# ES32F36xx register map
File version: 1.0
Registers are 32-bit, read-write, reset 0x0 unless marked. A register's access mark holds for its fields unless they carry their own. Offsets are from the block's base; [hi:lo] are bit positions; {n}, {i} and the like mark numbered series; 'fields as' and 'values as' point back to an identical list.

## DBGC
Base 0x4004A000
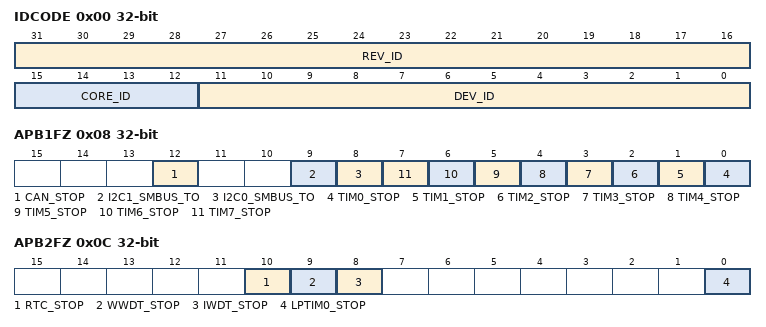
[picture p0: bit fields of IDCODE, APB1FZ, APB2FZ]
0x00 IDCODE read
  [31:16] REV_ID, [15:12] CORE_ID, [11:0] DEV_ID
0x08 APB1FZ
  [12] CAN_STOP, [9] I2C1_SMBUS_TO, [8] I2C0_SMBUS_TO, [n] TIM{n}_STOP (n=0..7)
0x0C APB2FZ
  [10] RTC_STOP, [9] WWDT_STOP, [8] IWDT_STOP, [0] LPTIM0_STOP

## QSPI
Base 0x4000D400
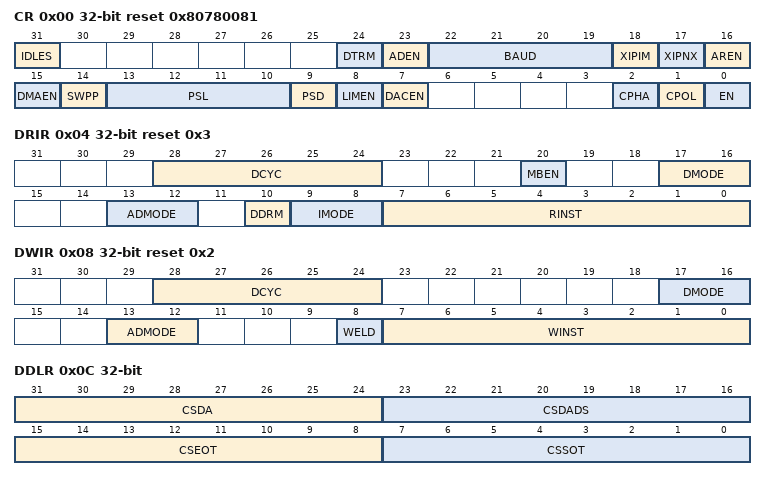
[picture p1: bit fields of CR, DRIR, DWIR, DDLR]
0x00 CR reset 0x80780081
  [31] IDLES read, [24] DTRM, [23] ADEN, [22:19] BAUD, [18] XIPIM, [17] XIPNX, [16] AREN, [15] DMAEN, [14] SWPP, [13:10] PSL, [9] PSD, [8] LIMEN, [7] DACEN, [2] CPHA, [1] CPOL, [0] EN
0x04 DRIR reset 0x3
  [28:24] DCYC, [20] MBEN, [17:16] DMODE, [13:12] ADMODE, [10] DDRM, [9:8] IMODE, [7:0] RINST
0x08 DWIR reset 0x2
  [28:24] DCYC, [17:16] DMODE, [13:12] ADMODE, [8] WELD, [7:0] WINST
0x0C DDLR
  [31:24] CSDA, [23:16] CSDADS, [15:8] CSEOT, [7:0] CSSOT
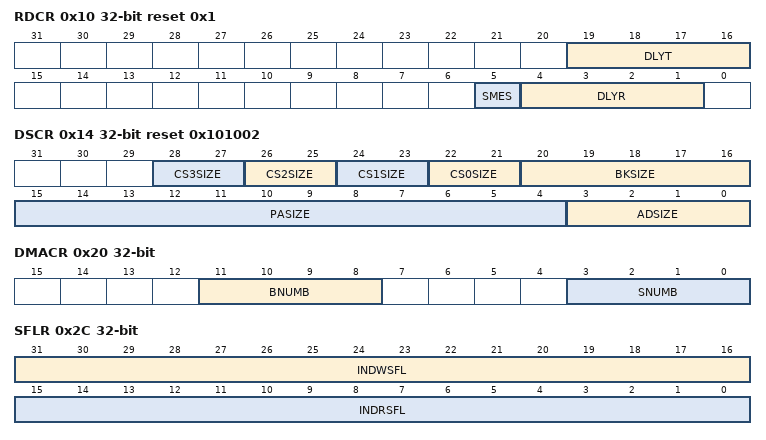
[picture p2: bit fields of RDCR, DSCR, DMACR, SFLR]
0x10 RDCR reset 0x1
  [19:16] DLYT, [5] SMES, [4:1] DLYR
0x14 DSCR reset 0x101002
  [2n+22:2n+21] CS{n}SIZE (n=0..3), [20:16] BKSIZE, [15:4] PASIZE, [3:0] ADSIZE
0x18 SPR reset 0x20
  [7:0] SRAMPS
0x1C IATR
  [31:0] INDTAD
0x20 DMACR
  [11:8] BNUMB, [3:0] SNUMB
0x24 RAR
  [31:0] READDR
0x28 MBR
  [7:0] MODEB
0x2C SFLR read
  [31:16] INDWSFL, [15:0] INDRSFL
0x30 TXHR reset 0x1
  [4:0] TXTH
0x34 RXHR reset 0x1
  [4:0] RXTH
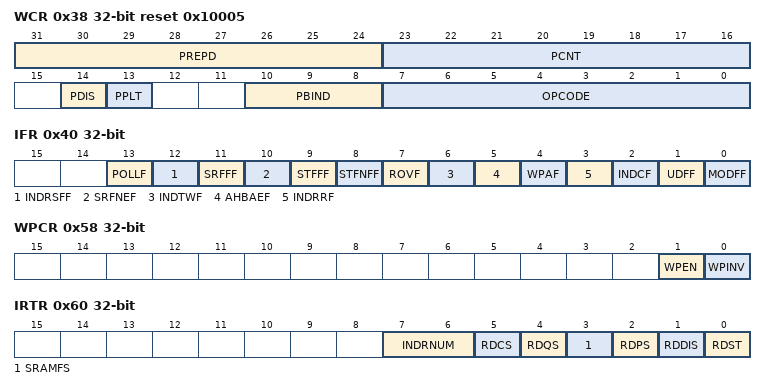
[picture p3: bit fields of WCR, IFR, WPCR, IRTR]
0x38 WCR reset 0x10005
  [31:24] PREPD, [23:16] PCNT, [14] PDIS, [13] PPLT, [10:8] PBIND, [7:0] OPCODE
0x3C PER reset 0xFFFFFFFF
  [31:0] PCYCN
0x40 IFR write1
  [13] POLLF read-clear-write1, [12] INDRSFF read-clear-write1, [11] SRFFF read-clear-write1, [10] SRFNEF read-clear-write1, [9] STFFF read-clear-write1, [8] STFNFF read-clear-write1, [7] ROVF read-clear-write1, [6] INDTWF read-clear-write1, [5] AHBAEF read-clear-write1, [4] WPAF read-clear-write1, [3] INDRRF read-clear-write1, [2] INDCF read-clear-write1, [1] UDFF read-clear-write1, [0] MODFF read-clear-write1
0x44 IMR
  [13:0] INTEN
0x50 WPLR
  [31:0] LBLKNUM
0x54 WPHR
  [31:0] HBLKNUM
0x58 WPCR
  [1] WPEN, [0] WPINV
0x60 IRTR write1
  [7:6] INDRNUM read, [5] RDCS read-clear-write1, [4] RDQS read, [3] SRAMFS read-clear-write1, [2] RDPS read, [1] RDDIS, [0] RDST
0x64 IRTWR
  [31:0] VAULE
0x68 IRTSAR
  [31:0] ADDR
0x6C IRTNR
  [31:0] NUM
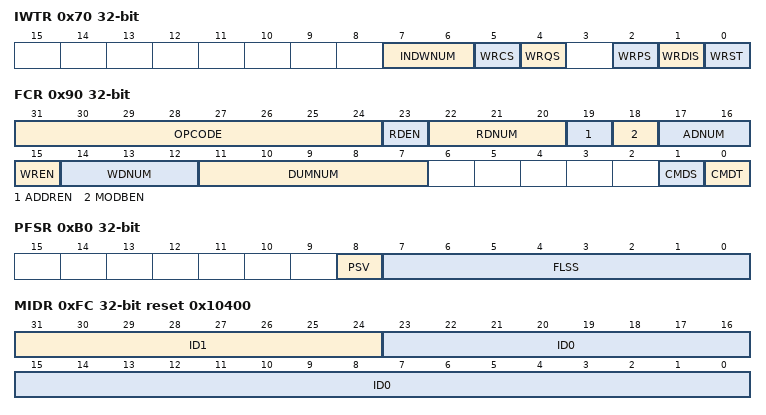
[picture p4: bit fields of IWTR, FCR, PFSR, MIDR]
0x70 IWTR write1
  [7:6] INDWNUM read, [5] WRCS read-clear-write1, [4] WRQS read, [2] WRPS read, [1] WRDIS, [0] WRST
0x74 IWTWR reset 0xFFFFFFFF
  [31:0] VAULE
0x78 IWTSAR
  [31:0] ADDR
0x7C IWTNR
  [31:0] NUM
0x80 ITARR reset 0x4
  [3:0] RNGW
0x90 FCR write1
  [31:24] OPCODE rw, [23] RDEN rw, [22:20] RDNUM rw, [19] ADDREN rw, [18] MODBEN rw, [17:16] ADNUM rw, [15] WREN rw, [14:12] WDNUM rw, [11:7] DUMNUM rw, [1] CMDS read, [0] CMDT
0x94 FCAR
  [31:0] CMDADR
0xA0 FCRLR read
  [31:0] CMDDL
0xA4 FCRHR read
  [31:0] CMDDH
0xA8 FCWLR read
  [31:0] CMDDL
0xAC FCWHR read
  [31:0] CMDDH
0xB0 PFSR read
  [8] PSV, [7:0] FLSS
0xFC MIDR read reset 0x10400
  [31:24] ID1, [23:0] ID0

## EBI
Base 0xA0000000
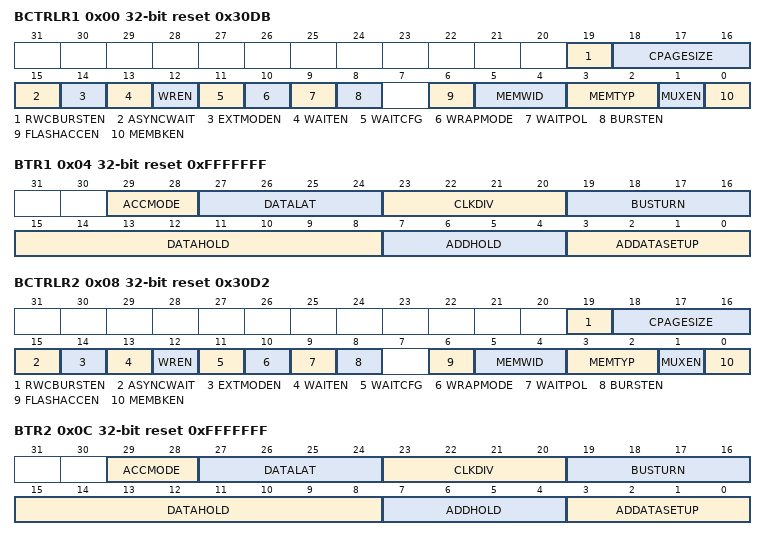
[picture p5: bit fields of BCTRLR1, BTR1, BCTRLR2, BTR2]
0x00 BCTRLR1 reset 0x30DB
  [19] RWCBURSTEN, [18:16] CPAGESIZE, [15] ASYNCWAIT, [14] EXTMODEN, [13] WAITEN, [12] WREN, [11] WAITCFG, [10] WRAPMODE, [9] WAITPOL, [8] BURSTEN, [6] FLASHACCEN, [5:4] MEMWID, [3:2] MEMTYP, [1] MUXEN, [0] MEMBKEN
0x04 BTR1 reset 0xFFFFFFF
  [29:28] ACCMODE, [27:24] DATALAT, [23:20] CLKDIV, [19:16] BUSTURN, [15:8] DATAHOLD, [7:4] ADDHOLD, [3:0] ADDATASETUP
0x08 BCTRLR2 reset 0x30D2
  fields as BCTRLR1
0x0C BTR2 reset 0xFFFFFFF
  fields as BTR1
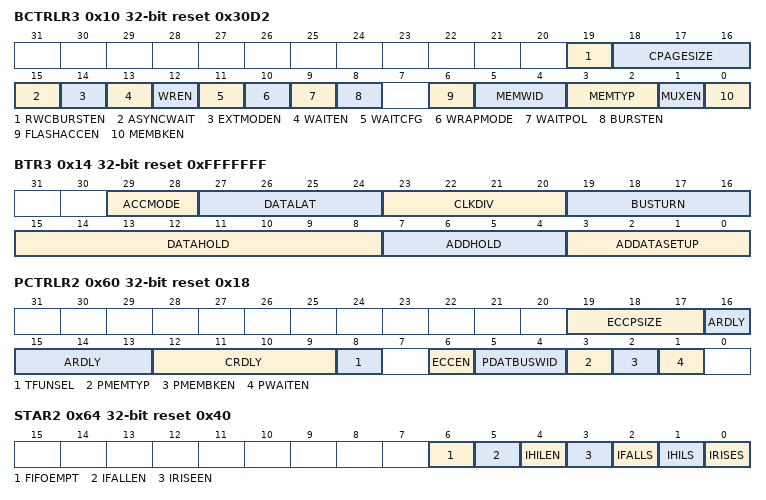
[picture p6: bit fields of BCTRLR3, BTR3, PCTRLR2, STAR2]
0x10 BCTRLR3 reset 0x30D2
  fields as BCTRLR1
0x14 BTR3 reset 0xFFFFFFF
  fields as BTR1
0x60 PCTRLR2 reset 0x18
  [19:17] ECCPSIZE, [16:13] ARDLY, [12:9] CRDLY, [8] TFUNSEL, [6] ECCEN, [5:4] PDATBUSWID, [3] PMEMTYP, [2] PMEMBKEN, [1] PWAITEN
0x64 STAR2 reset 0x40
  [6] FIFOEMPT read, [5] IFALLEN, [4] IHILEN, [3] IRISEEN, [2] IFALLS, [1] IHILS, [0] IRISES
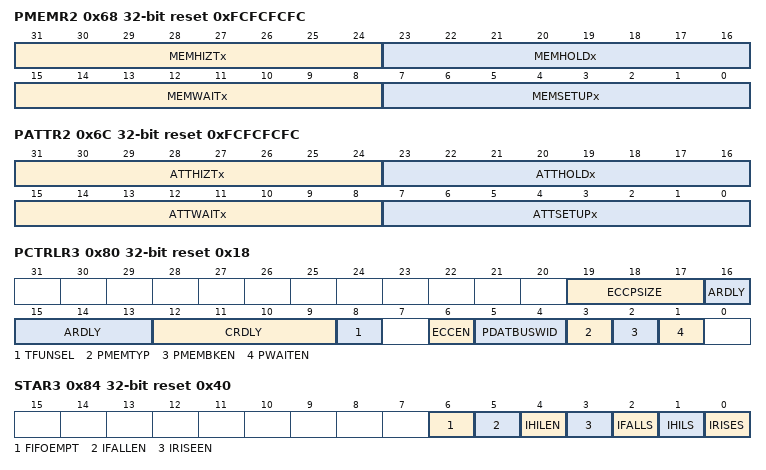
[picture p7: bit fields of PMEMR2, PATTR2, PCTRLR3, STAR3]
0x68 PMEMR2 reset 0xFCFCFCFC
  [31:24] MEMHIZTx, [23:16] MEMHOLDx, [15:8] MEMWAITx, [7:0] MEMSETUPx
0x6C PATTR2 reset 0xFCFCFCFC
  [31:24] ATTHIZTx, [23:16] ATTHOLDx, [15:8] ATTWAITx, [7:0] ATTSETUPx
0x74 ECCRESULT2
  [31:0] ECCRESULTx
0x80 PCTRLR3 reset 0x18
  fields as PCTRLR2
0x84 STAR3 reset 0x40
  fields as STAR2
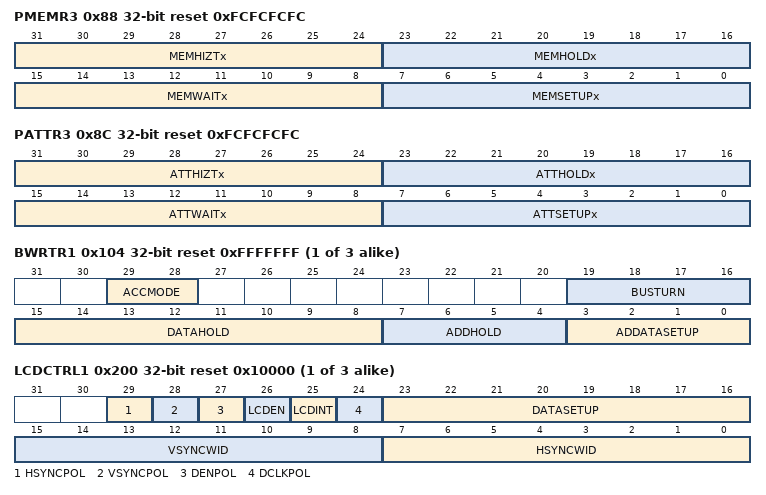
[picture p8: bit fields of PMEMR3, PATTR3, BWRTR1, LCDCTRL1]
0x88 PMEMR3 reset 0xFCFCFCFC
  [31:24] MEMHIZTx, [23:16] MEMHOLDx, [15:8] MEMWAITx, [7:0] MEMSETUPx
0x8C PATTR3 reset 0xFCFCFCFC
  [31:24] ATTHIZTx, [23:16] ATTHOLDx, [15:8] ATTWAITx, [7:0] ATTSETUPx
0x94 ECCRESULT3
  [31:0] ECCRESULTx
{0xFC+8i} BWRTR{i} reset 0xFFFFFFF (i=1..3)
  [29:28] ACCMODE, [19:16] BUSTURN, [15:8] DATAHOLD, [7:4] ADDHOLD, [3:0] ADDATASETUP
{0x1F0+0x10*i} LCDCTRL{i} reset 0x10000 (i=1..3)
  [29] HSYNCPOL, [28] VSYNCPOL, [27] DENPOL, [26] LCDEN, [25] LCDINT, [24] DCLKPOL, [23:16] DATASETUP, [15:8] VSYNCWID, [7:0] HSYNCWID
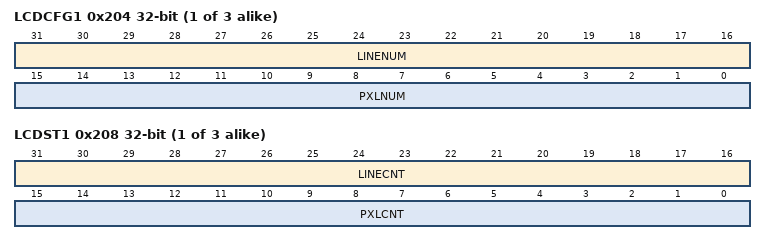
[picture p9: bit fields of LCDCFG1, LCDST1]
{0x1F4+0x10*i} LCDCFG{i} (i=1..3)
  [31:16] LINENUM, [15:0] PXLNUM
{0x1F8+0x10*i} LCDST{i} read (i=1..3)
  [31:16] LINECNT, [15:0] PXLCNT

## DAC0
Base 0x40045000
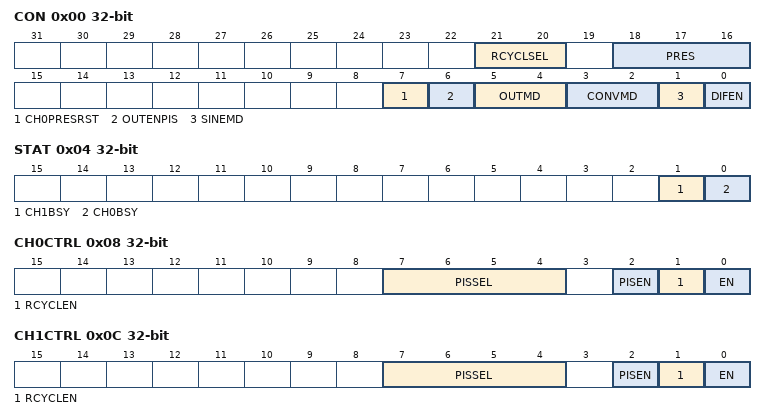
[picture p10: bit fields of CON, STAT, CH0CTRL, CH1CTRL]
0x00 CON
  [21:20] RCYCLSEL, [18:16] PRES, [7] CH0PRESRST, [6] OUTENPIS, [5:4] OUTMD, [3:2] CONVMD, [1] SINEMD, [0] DIFEN
0x04 STAT read
  [1] CH1BSY, [0] CH0BSY
0x08 CH0CTRL
  [7:4] PISSEL, [2] PISEN, [1] RCYCLEN, [0] EN
0x0C CH1CTRL
  [7:4] PISSEL, [2] PISEN, [1] RCYCLEN, [0] EN
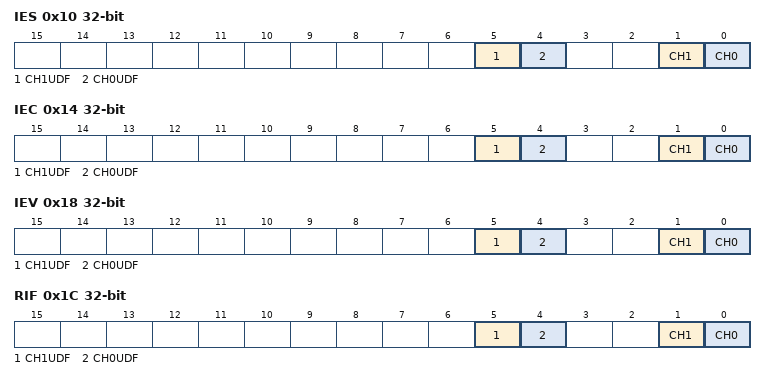
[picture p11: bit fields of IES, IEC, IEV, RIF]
0x10 IES write
  [5] CH1UDF, [4] CH0UDF, [1] CH1, [0] CH0
0x14 IEC write
  [5] CH1UDF, [4] CH0UDF, [1] CH1, [0] CH0
0x18 IEV read
  [5] CH1UDF, [4] CH0UDF, [1] CH1, [0] CH0
0x1C RIF read
  [5] CH1UDF, [4] CH0UDF, [1] CH1, [0] CH0
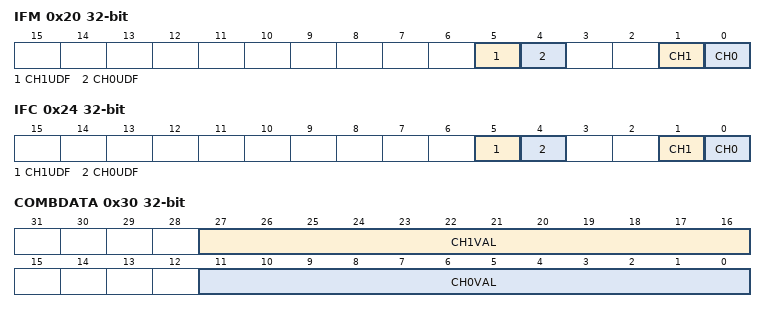
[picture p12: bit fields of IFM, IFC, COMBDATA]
0x20 IFM read
  [5] CH1UDF, [4] CH0UDF, [1] CH1, [0] CH0
0x24 IFC write1
  [5] CH1UDF, [4] CH0UDF, [1] CH1, [0] CH0
0x28 CH0DATA
  [11:0] VAL
0x2C CH1DATA
  [11:0] VAL
0x30 COMBDATA write
  [27:16] CH1VAL, [11:0] CH0VAL
0x34 CAL
  [31] SELF_CALEN

## PIS
Base 0x40086000
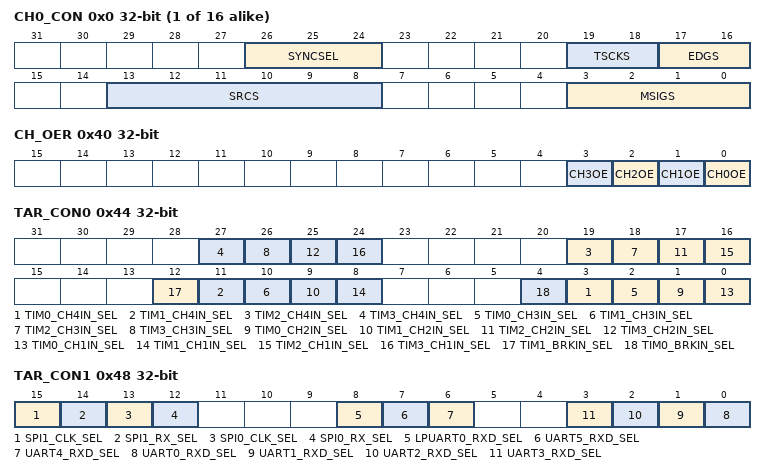
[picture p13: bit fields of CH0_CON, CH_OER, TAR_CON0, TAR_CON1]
{0x0+4i} CH{i}_CON (i=0..15)
  [26:24] SYNCSEL, [19:18] TSCKS, [17:16] EDGS, [13:8] SRCS, [3:0] MSIGS
0x40 CH_OER
  [n] CH{n}OE (n=0..3)
0x44 TAR_CON0
  [8n+3] TIM{n}_CH4IN_SEL (n=0..3), [8n+2] TIM{n}_CH3IN_SEL (n=0..3), [8n+1] TIM{n}_CH2IN_SEL (n=0..3), [8n] TIM{n}_CH1IN_SEL (n=0..3), [12] TIM1_BRKIN_SEL, [4] TIM0_BRKIN_SEL
0x48 TAR_CON1
  [15] SPI1_CLK_SEL, [14] SPI1_RX_SEL, [13] SPI0_CLK_SEL, [12] SPI0_RX_SEL, [8] LPUART0_RXD_SEL, [7] UART5_RXD_SEL, [6] UART4_RXD_SEL, [n] UART{n}_RXD_SEL (n=0..3)
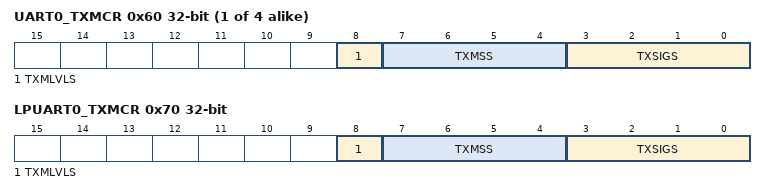
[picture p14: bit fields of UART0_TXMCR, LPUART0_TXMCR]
{0x60+4i} UART{i}_TXMCR (i=0..3)
  [8] TXMLVLS, [7:4] TXMSS, [3:0] TXSIGS
0x70 LPUART0_TXMCR
  [8] TXMLVLS, [7:4] TXMSS, [3:0] TXSIGS
